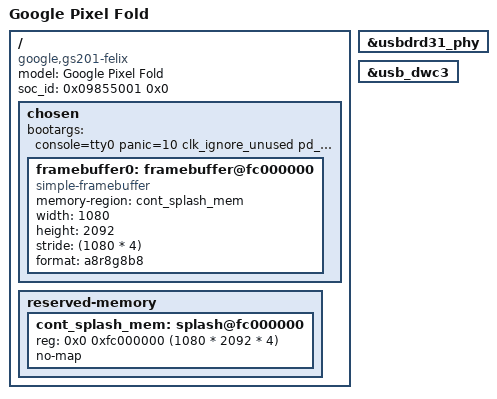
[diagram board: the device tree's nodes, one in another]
// SPDX-License-Identifier: GPL-2.0-only
/*
 * Google Pixel Fold (felix), first light.
 *
 * Same GS201 silicon as the Pixel 7 Pro. This board file brings up USB,
 * the cluster watchdogs, and the cover framebuffer the bootloader is
 * already scanning. It does not describe either panel or either touch
 * controller. The inner panel has no node that could drive it.
 */

/dts-v1/;

#include "gs201.dtsi"

/ {
	model = "Google Pixel Fold";
	compatible = "google,gs201-felix", "google,gs201";

	/*
	 * ABL matches (product id 0x09855000 | major rev). This phone is
	 * GS201 MP1.0, package mode 0, SoC rev 2: the same B0 id as cheetah.
	 * The image packer appends a second DTB with 0x09855000.
	 */
	soc_id = <0x09855001 0x0>;

	chosen {
		/*
		 * ABL requires bootargs and appends its own, including
		 * console=null. No UFS probe: storage stays off until this
		 * phone's guard has been checked. Nothing here writes a
		 * display register. The framebuffer below is the cover plane
		 * read from DPP2 on the first boot (1080x2092 at 0xfc000000).
		 * The inner plane, DPP0 at 0xfac00000, is not described.
		 */
		bootargs = "console=tty0 panic=10 clk_ignore_unused pd_ignore_unused rdinit=/init";
		#address-cells = <2>;
		#size-cells = <1>;
		ranges;

		framebuffer0: framebuffer@fc000000 {
			compatible = "simple-framebuffer";
			memory-region = <&cont_splash_mem>;
			width = <1080>;
			height = <2092>;
			stride = <(1080 * 4)>;
			format = "a8r8g8b8";
		};
	};

	reserved-memory {
		#address-cells = <2>;
		#size-cells = <1>;
		ranges;

		cont_splash_mem: splash@fc000000 {
			reg = <0x0 0xfc000000 (1080 * 2092 * 4)>;
			no-map;
		};
	};
};

&usbdrd31_phy {
	status = "okay";
};

&usb_dwc3 {
	status = "okay";
};
